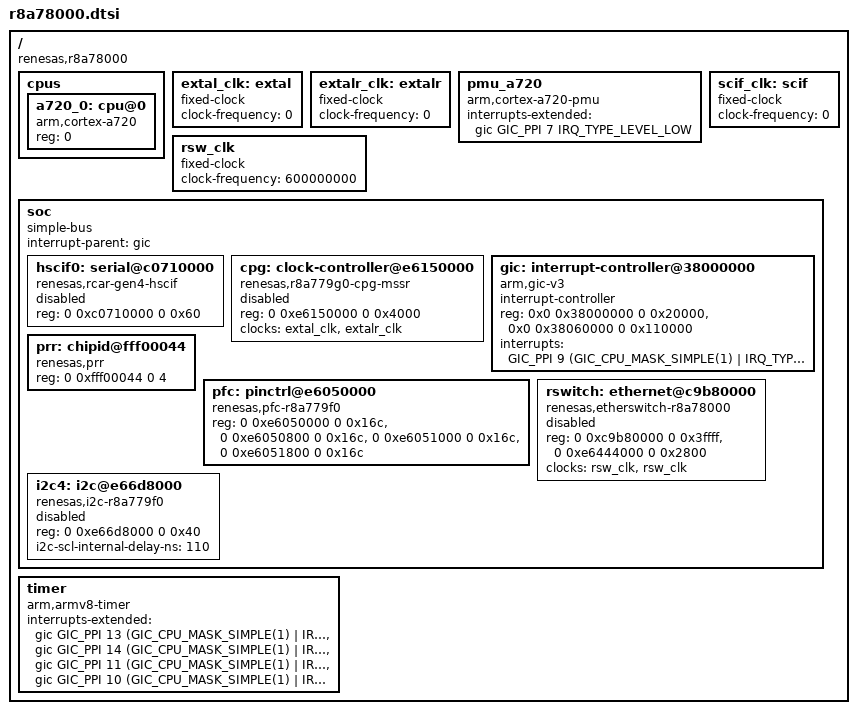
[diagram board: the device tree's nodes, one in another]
// SPDX-License-Identifier: (GPL-2.0-only OR BSD-2-Clause)
/*
 * Device Tree Source for the R-Car X5H (R8A78000) SoC
 *
 * Copyright (C) 2023 Renesas Electronics Corp.
 */

#include <dt-bindings/interrupt-controller/arm-gic.h>

/ {
	compatible = "renesas,r8a78000";
	#address-cells = <2>;
	#size-cells = <2>;

	cpus {
		#address-cells = <1>;
		#size-cells = <0>;

		a720_0: cpu@0 {
			compatible = "arm,cortex-a720";
			reg = <0>;
			device_type = "cpu";
		};
	};

	extal_clk: extal {
		compatible = "fixed-clock";
		#clock-cells = <0>;
		/* This value must be overridden by the board */
		clock-frequency = <0>;
	};

	extalr_clk: extalr {
		compatible = "fixed-clock";
		#clock-cells = <0>;
		/* This value must be overridden by the board */
		clock-frequency = <0>;
	};

	pmu_a720 {
		compatible = "arm,cortex-a720-pmu";
		interrupts-extended = <&gic GIC_PPI 7 IRQ_TYPE_LEVEL_LOW>;
	};

	/* External SCIF clock - to be overridden by boards that provide it */
	scif_clk: scif {
		compatible = "fixed-clock";
		#clock-cells = <0>;
		clock-frequency = <0>;
	};

	rsw_clk: rsw_clk {
		compatible = "fixed-clock";
		clock-frequency = <600000000>;
		#clock-cells = <0>;
	};

	soc: soc {
		compatible = "simple-bus";
		interrupt-parent = <&gic>;
		#address-cells = <2>;
		#size-cells = <2>;
		ranges;

		hscif0: serial@c0710000 {
			compatible = "renesas,rcar-gen4-hscif", "renesas,hscif";
			reg = <0 0xc0710000 0 0x60>;
			status = "disabled";
		};

		cpg: clock-controller@e6150000 {
			compatible = "renesas,r8a779g0-cpg-mssr";
			reg = <0 0xe6150000 0 0x4000>;
			clocks = <&extal_clk>, <&extalr_clk>;
			clock-names = "extal", "extalr";
			#clock-cells = <2>;
			#power-domain-cells = <0>;
			#reset-cells = <1>;
			status = "disabled";
		};

		gic: interrupt-controller@38000000 {
			compatible = "arm,gic-v3";
			#interrupt-cells = <3>;
			#address-cells = <0>;
			interrupt-controller;
			reg = <0x0 0x38000000 0 0x20000>,
			      <0x0 0x38060000 0 0x110000>;
			interrupts = <GIC_PPI 9
				      (GIC_CPU_MASK_SIMPLE(1) | IRQ_TYPE_LEVEL_HIGH)>;
		};

		prr: chipid@fff00044 {
			compatible = "renesas,prr";
			reg = <0 0xfff00044 0 4>;
		};

		pfc: pinctrl@e6050000 {
			compatible = "renesas,pfc-r8a779f0";
			reg = <0 0xe6050000 0 0x16c>, <0 0xe6050800 0 0x16c>,
			<0 0xe6051000 0 0x16c>, <0 0xe6051800 0 0x16c>;
		};

		rswitch: ethernet@c9b80000 {
			compatible = "renesas,etherswitch-r8a78000",
					"renesas,etherswitch";
			reg = <0 0xc9b80000 0 0x3ffff>,
				<0 0xe6444000 0 0x2800>;
			reg-names = "iobase", "serdes";
			#address-cells = <1>;
			#size-cells = <0>;
			clocks = <&rsw_clk>, <&rsw_clk>;
			clock-names = "rsw2", "eth-phy";
			status = "disabled";
		};

		i2c4: i2c@e66d8000 {
			compatible = "renesas,i2c-r8a779f0",
				"renesas,rcar-gen4-i2c";
			reg = <0 0xe66d8000 0 0x40>;
			i2c-scl-internal-delay-ns = <110>;
			#address-cells = <1>;
			#size-cells = <0>;
			status = "disabled";
		};
	};

	timer {
		compatible = "arm,armv8-timer";
		interrupts-extended = <&gic GIC_PPI 13 (GIC_CPU_MASK_SIMPLE(1) | IRQ_TYPE_LEVEL_LOW)>,
				      <&gic GIC_PPI 14 (GIC_CPU_MASK_SIMPLE(1) | IRQ_TYPE_LEVEL_LOW)>,
				      <&gic GIC_PPI 11 (GIC_CPU_MASK_SIMPLE(1) | IRQ_TYPE_LEVEL_LOW)>,
				      <&gic GIC_PPI 10 (GIC_CPU_MASK_SIMPLE(1) | IRQ_TYPE_LEVEL_LOW)>;
	};
};
